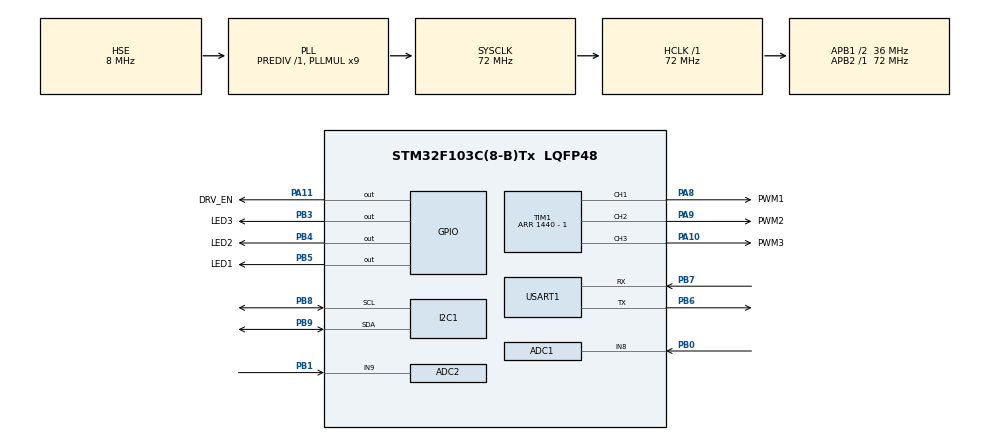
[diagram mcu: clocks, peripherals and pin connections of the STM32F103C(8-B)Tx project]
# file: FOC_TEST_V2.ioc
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ADC1.Channel-14\#ChannelRegularConversion=ADC_CHANNEL_8
ADC1.EnableInjectedConversion=DISABLE
ADC1.EnableRegularConversion=ENABLE
ADC1.ExternalTrigInjecConv=ADC_INJECTED_SOFTWARE_START
ADC1.InjNumberOfConversion=1
ADC1.Mode=ADC_DUALMODE_REGSIMULT
ADC1.NbrOfConversionFlag=1
ADC1.Rank-14\#ChannelRegularConversion=1
ADC1.SamplingTime-14\#ChannelRegularConversion=ADC_SAMPLETIME_1CYCLE_5
ADC1.master=1
ADC2.Channel-12\#ChannelRegularConversion=ADC_CHANNEL_9
ADC2.EnableInjectedConversion=DISABLE
ADC2.EnableRegularConversion=ENABLE
ADC2.Mode=ADC_DUALMODE_REGSIMULT
ADC2.NbrOfConversionFlag=1
ADC2.Rank-12\#ChannelRegularConversion=1
ADC2.SamplingTime-12\#ChannelRegularConversion=ADC_SAMPLETIME_1CYCLE_5
Dma.ADC1.1.Direction=DMA_PERIPH_TO_MEMORY
Dma.ADC1.1.Instance=DMA1_Channel1
Dma.ADC1.1.MemDataAlignment=DMA_MDATAALIGN_WORD
Dma.ADC1.1.MemInc=DMA_MINC_ENABLE
Dma.ADC1.1.Mode=DMA_CIRCULAR
Dma.ADC1.1.PeriphDataAlignment=DMA_PDATAALIGN_WORD
Dma.ADC1.1.PeriphInc=DMA_PINC_DISABLE
Dma.ADC1.1.Priority=DMA_PRIORITY_HIGH
Dma.I2C1_RX.0.Direction=DMA_PERIPH_TO_MEMORY
Dma.I2C1_RX.0.Instance=DMA1_Channel7
Dma.I2C1_RX.0.MemDataAlignment=DMA_MDATAALIGN_BYTE
Dma.I2C1_RX.0.MemInc=DMA_MINC_ENABLE
Dma.I2C1_RX.0.Mode=DMA_NORMAL
Dma.I2C1_RX.0.PeriphDataAlignment=DMA_PDATAALIGN_BYTE
Dma.I2C1_RX.0.PeriphInc=DMA_PINC_DISABLE
Dma.I2C1_RX.0.Priority=DMA_PRIORITY_LOW
Dma.Request0=I2C1_RX
Dma.Request1=ADC1
Dma.Request2=USART1_RX
Dma.Request3=USART1_TX
Dma.USART1_RX.2.Direction=DMA_PERIPH_TO_MEMORY
Dma.USART1_RX.2.Instance=DMA1_Channel5
Dma.USART1_RX.2.MemDataAlignment=DMA_MDATAALIGN_BYTE
Dma.USART1_RX.2.MemInc=DMA_MINC_ENABLE
Dma.USART1_RX.2.Mode=DMA_NORMAL
Dma.USART1_RX.2.PeriphDataAlignment=DMA_PDATAALIGN_BYTE
Dma.USART1_RX.2.PeriphInc=DMA_PINC_DISABLE
Dma.USART1_RX.2.Priority=DMA_PRIORITY_LOW
Dma.USART1_TX.3.Direction=DMA_MEMORY_TO_PERIPH
Dma.USART1_TX.3.Instance=DMA1_Channel4
Dma.USART1_TX.3.MemDataAlignment=DMA_MDATAALIGN_BYTE
Dma.USART1_TX.3.MemInc=DMA_MINC_ENABLE
Dma.USART1_TX.3.Mode=DMA_NORMAL
Dma.USART1_TX.3.PeriphDataAlignment=DMA_PDATAALIGN_BYTE
Dma.USART1_TX.3.PeriphInc=DMA_PINC_DISABLE
Dma.USART1_TX.3.Priority=DMA_PRIORITY_LOW
I2C1.I2C_Mode=I2C_Fast
Mcu.Family=STM32F1
Mcu.Name=STM32F103C(8-B)Tx
Mcu.Package=LQFP48
NVIC.DMA1_Channel1_IRQn=true\:0\:0\:false\:false\:true\:false\:true\:true
NVIC.DMA1_Channel4_IRQn=true\:0\:0\:false\:false\:true\:false\:true\:true
NVIC.DMA1_Channel5_IRQn=true\:0\:0\:false\:false\:true\:false\:true\:true
NVIC.DMA1_Channel7_IRQn=true\:0\:0\:false\:false\:true\:false\:true\:true
NVIC.I2C1_EV_IRQn=true\:0\:0\:false\:false\:true\:true\:true\:true
NVIC.PriorityGroup=NVIC_PRIORITYGROUP_4
NVIC.TIM1_UP_IRQn=true\:0\:0\:false\:false\:true\:true\:true\:true
NVIC.TIM3_IRQn=true\:0\:0\:false\:false\:true\:true\:true\:true
NVIC.USART1_IRQn=true\:0\:0\:false\:false\:true\:true\:true\:true
PA10.GPIO_Label=PWM3
PA10.Signal=S_TIM1_CH3
PA11.GPIO_Label=DRV_EN
PA11.Signal=GPIO_Output
PA13.Mode=Serial_Wire
PA13.Signal=SYS_JTMS-SWDIO
PA14.Mode=Serial_Wire
PA14.Signal=SYS_JTCK-SWCLK
PA8.GPIO_Label=PWM1
PA8.Signal=S_TIM1_CH1
PA9.GPIO_Label=PWM2
PA9.Signal=S_TIM1_CH2
PB0.Signal=ADCx_IN8
PB1.Signal=ADCx_IN9
PB3.GPIO_Label=LED3
PB3.Signal=GPIO_Output
PB4.GPIO_Label=LED2
PB4.Signal=GPIO_Output
PB5.GPIO_Label=LED1
PB5.Signal=GPIO_Output
PB6.Mode=Asynchronous
PB6.Signal=USART1_TX
PB7.Mode=Asynchronous
PB7.Signal=USART1_RX
PB8.Mode=I2C
PB8.Signal=I2C1_SCL
PB9.Mode=I2C
PB9.Signal=I2C1_SDA
PD0-OSC_IN.Mode=HSE-External-Oscillator
PD0-OSC_IN.Signal=RCC_OSC_IN
PD1-OSC_OUT.Mode=HSE-External-Oscillator
PD1-OSC_OUT.Signal=RCC_OSC_OUT
ProjectManager.HeapSize=0x200
ProjectManager.StackSize=0x400
ProjectManager.TargetToolchain=MDK-ARM V5.32
RCC.ADCPresc=RCC_ADCPCLK2_DIV6
RCC.AHBFreq_Value=72000000
RCC.APB1CLKDivider=RCC_HCLK_DIV2
RCC.APB1Freq_Value=36000000
RCC.APB1TimFreq_Value=72000000
RCC.APB2Freq_Value=72000000
RCC.APB2TimFreq_Value=72000000
RCC.HCLKFreq_Value=72000000
RCC.PLLMUL=RCC_PLL_MUL9
RCC.PLLSourceVirtual=RCC_PLLSOURCE_HSE
RCC.SYSCLKFreq_VALUE=72000000
RCC.SYSCLKSource=RCC_SYSCLKSOURCE_PLLCLK
RCC.USBFreq_Value=72000000
SH.ADCx_IN8.0=ADC1_IN8,IN8
SH.ADCx_IN9.0=ADC2_IN9,IN9
SH.S_TIM1_CH1.0=TIM1_CH1,PWM Generation1 CH1
SH.S_TIM1_CH2.0=TIM1_CH2,PWM Generation2 CH2
SH.S_TIM1_CH3.0=TIM1_CH3,PWM Generation3 CH3
TIM1.Channel-PWM\ Generation1\ CH1=TIM_CHANNEL_1
TIM1.Channel-PWM\ Generation2\ CH2=TIM_CHANNEL_2
TIM1.Channel-PWM\ Generation3\ CH3=TIM_CHANNEL_3
TIM1.CounterMode=TIM_COUNTERMODE_CENTERALIGNED1
TIM1.OCPolarity_1=TIM_OCPOLARITY_LOW
TIM1.OCPolarity_2=TIM_OCPOLARITY_LOW
TIM1.OCPolarity_3=TIM_OCPOLARITY_LOW
TIM1.Period=1440 - 1
USART1.VirtualMode=VM_ASYNC
VP_TIM1_VS_ClockSourceINT.Mode=Internal
VP_TIM3_VS_ClockSourceINT.Mode=Internal
VP_TIM4_VS_ClockSourceINT.Mode=Internal
board=custom

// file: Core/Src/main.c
/* USER CODE BEGIN Header */
/**
  ******************************************************************************
  * @file           : main.c
  * @brief          : Main program body
  ******************************************************************************
  * @attention
  *
  * Copyright (c) 2023 STMicroelectronics.
  * All rights reserved.
  *
  * This software is licensed under terms that can be found in the LICENSE file
  * in the root directory of this software component.
  * If no LICENSE file comes with this software, it is provided AS-IS.
  *
  ******************************************************************************
  */
/* USER CODE END Header */
#include "main.h"
#include "adc.h"
#include "dma.h"
#include "i2c.h"
#include "tim.h"
#include "usart.h"
#include "gpio.h"

/* USER CODE BEGIN Includes */
#include "BSP_ADC.h"
#include "BSP_MT6701.h"
#include "FOC_Ctrl.h"
#include "TIM_IT_Server.h"
#include "LPF.h"
#include "IQmathLib.h"
/* USER CODE END Includes */

void SystemClock_Config(void);

int main(void)
  {

  /* MCU Configuration--------------------------------------------------------*/

  /* Reset of all peripherals, Initializes the Flash interface and the Systick. */
  HAL_Init();

  /* Configure the system clock */
  SystemClock_Config();

  /* Initialize all configured peripherals */
  MX_GPIO_Init();
  MX_DMA_Init();
  MX_ADC1_Init();
  MX_I2C1_Init();
  MX_TIM1_Init();
  MX_TIM3_Init();
  MX_ADC2_Init();
  MX_USART1_UART_Init();
  MX_TIM4_Init();
  /* USER CODE BEGIN 2 */
	ADC_Init();
	TIM_Init();
	FOC_Init();
	//LPF_Init();

  /* USER CODE END 2 */

  /* Infinite loop */
  while (1)
  {

    /* USER CODE BEGIN 3 */
		FOC_Ctrl();

  }
  /* USER CODE END 3 */
}

void SystemClock_Config(void)
{
  RCC_OscInitTypeDef RCC_OscInitStruct = {0};
  RCC_ClkInitTypeDef RCC_ClkInitStruct = {0};
  RCC_PeriphCLKInitTypeDef PeriphClkInit = {0};

  /** Initializes the RCC Oscillators according to the specified parameters
  * in the RCC_OscInitTypeDef structure.
  */
  RCC_OscInitStruct.OscillatorType = RCC_OSCILLATORTYPE_HSE;
  RCC_OscInitStruct.HSEState = RCC_HSE_ON;
  RCC_OscInitStruct.HSEPredivValue = RCC_HSE_PREDIV_DIV1;
  RCC_OscInitStruct.HSIState = RCC_HSI_ON;
  RCC_OscInitStruct.PLL.PLLState = RCC_PLL_ON;
  RCC_OscInitStruct.PLL.PLLSource = RCC_PLLSOURCE_HSE;
  RCC_OscInitStruct.PLL.PLLMUL = RCC_PLL_MUL9;
  if (HAL_RCC_OscConfig(&RCC_OscInitStruct) != HAL_OK)
  {
    Error_Handler();
  }

  /** Initializes the CPU, AHB and APB buses clocks
  */
  RCC_ClkInitStruct.ClockType = RCC_CLOCKTYPE_HCLK|RCC_CLOCKTYPE_SYSCLK
                              |RCC_CLOCKTYPE_PCLK1|RCC_CLOCKTYPE_PCLK2;
  RCC_ClkInitStruct.SYSCLKSource = RCC_SYSCLKSOURCE_PLLCLK;
  RCC_ClkInitStruct.AHBCLKDivider = RCC_SYSCLK_DIV1;
  RCC_ClkInitStruct.APB1CLKDivider = RCC_HCLK_DIV2;
  RCC_ClkInitStruct.APB2CLKDivider = RCC_HCLK_DIV1;

  if (HAL_RCC_ClockConfig(&RCC_ClkInitStruct, FLASH_LATENCY_2) != HAL_OK)
  {
    Error_Handler();
  }
  PeriphClkInit.PeriphClockSelection = RCC_PERIPHCLK_ADC;
  PeriphClkInit.AdcClockSelection = RCC_ADCPCLK2_DIV6;
  if (HAL_RCCEx_PeriphCLKConfig(&PeriphClkInit) != HAL_OK)
  {
    Error_Handler();
  }
}

void Error_Handler(void)
{
  __disable_irq();
  while (1)
  {
  }
}
